# f28e12x_pwm_xbar_regs register map
Vendor: Texas Instruments
Peripheral module from a debugger description file (folder C2000).
Address unit: 16 bits
Registers are 32-bit, read-write, no defined reset value unless marked. A register's access mark holds for its fields unless they carry their own. Offsets are as the file gives them; lines under a group give offsets from that group; [hi:lo] are bit positions; {n}, {i} and the like mark numbered series; 'fields as' and 'values as' point back to an identical list; <NAME> marks a mode.

## PWM_XBAR_REGS — PWM XBAR Registers
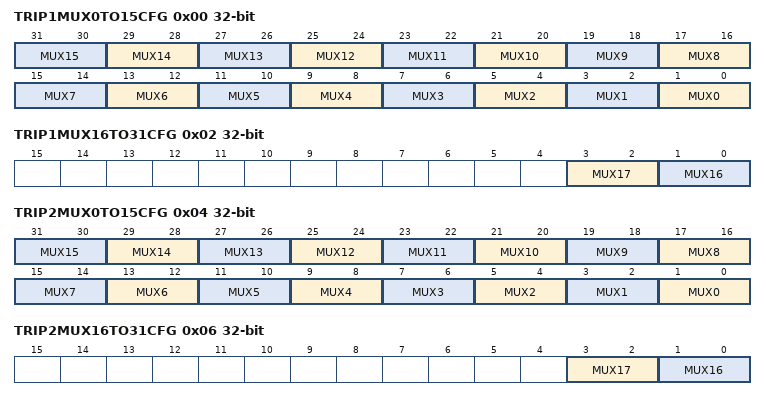
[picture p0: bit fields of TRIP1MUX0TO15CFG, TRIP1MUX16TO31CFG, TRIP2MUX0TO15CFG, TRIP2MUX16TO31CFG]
0x00 TRIP1MUX0TO15CFG — PWM XBAR Mux Configuration for Output1
  [2n+1:2n] MUX{n} (n=0..15) — MUX{n} Configuration for OUT1 of EPWM-XBAR
0x02 TRIP1MUX16TO31CFG — PWM XBAR Mux Configuration for Output1
  [3:2] MUX17 — MUX17 Configuration for OUT1 of EPWM-XBAR
  [1:0] MUX16 — MUX16 Configuration for OUT1 of EPWM-XBAR
0x04 TRIP2MUX0TO15CFG — PWM XBAR Mux Configuration for Output2
  [2n+1:2n] MUX{n} (n=0..15) — MUX{n} Configuration for OUT2 of EPWM-XBAR
0x06 TRIP2MUX16TO31CFG — PWM XBAR Mux Configuration for Output2
  [3:2] MUX17 — MUX17 Configuration for OUT2 of EPWM-XBAR
  [1:0] MUX16 — MUX16 Configuration for OUT2 of EPWM-XBAR
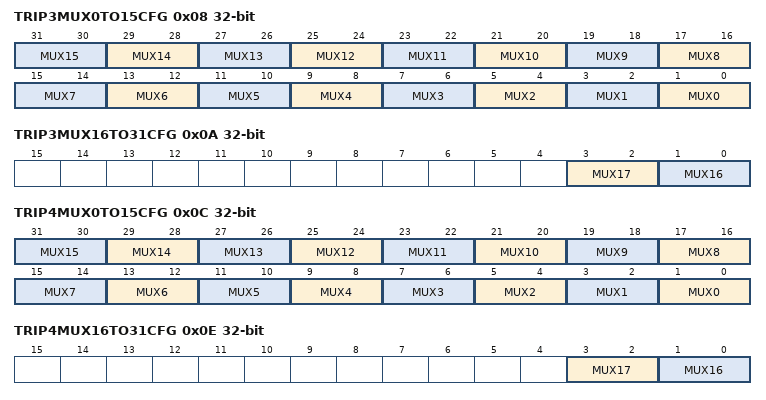
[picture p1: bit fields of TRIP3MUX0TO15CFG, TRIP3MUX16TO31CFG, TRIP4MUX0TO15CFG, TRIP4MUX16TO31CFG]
0x08 TRIP3MUX0TO15CFG — PWM XBAR Mux Configuration for Output3
  [2n+1:2n] MUX{n} (n=0..15) — MUX{n} Configuration for OUT3 of EPWM-XBAR
0x0A TRIP3MUX16TO31CFG — PWM XBAR Mux Configuration for Output3
  [3:2] MUX17 — MUX17 Configuration for OUT3 of EPWM-XBAR
  [1:0] MUX16 — MUX16 Configuration for OUT3 of EPWM-XBAR
0x0C TRIP4MUX0TO15CFG — PWM XBAR Mux Configuration for Output4
  [2n+1:2n] MUX{n} (n=0..15) — MUX{n} Configuration for OUT4 of EPWM-XBAR
0x0E TRIP4MUX16TO31CFG — PWM XBAR Mux Configuration for Output4
  [3:2] MUX17 — MUX17 Configuration for OUT4 of EPWM-XBAR
  [1:0] MUX16 — MUX16 Configuration for OUT4 of EPWM-XBAR
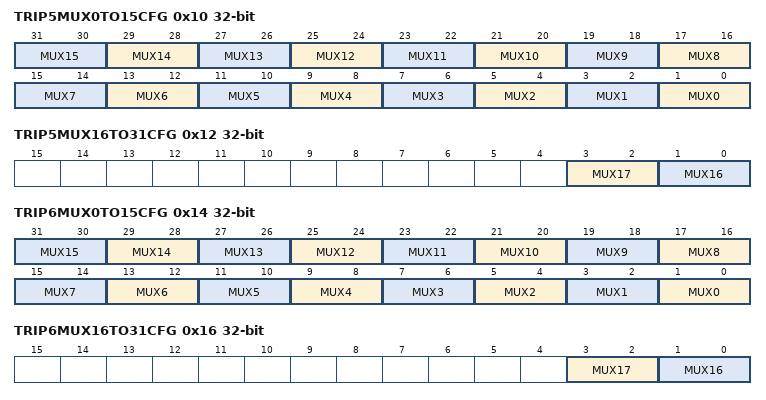
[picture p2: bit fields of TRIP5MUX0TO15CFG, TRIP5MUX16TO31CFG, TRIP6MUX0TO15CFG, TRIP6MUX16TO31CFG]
0x10 TRIP5MUX0TO15CFG — PWM XBAR Mux Configuration for Output5
  [2n+1:2n] MUX{n} (n=0..15) — MUX{n} Configuration for OUT5 of EPWM-XBAR
0x12 TRIP5MUX16TO31CFG — PWM XBAR Mux Configuration for Output5
  [3:2] MUX17 — MUX17 Configuration for OUT5 of EPWM-XBAR
  [1:0] MUX16 — MUX16 Configuration for OUT5 of EPWM-XBAR
0x14 TRIP6MUX0TO15CFG — PWM XBAR Mux Configuration for Output6
  [2n+1:2n] MUX{n} (n=0..15) — MUX{n} Configuration for OUT6 of EPWM-XBAR
0x16 TRIP6MUX16TO31CFG — PWM XBAR Mux Configuration for Output6
  [3:2] MUX17 — MUX17 Configuration for OUT6 of EPWM-XBAR
  [1:0] MUX16 — MUX16 Configuration for OUT6 of EPWM-XBAR
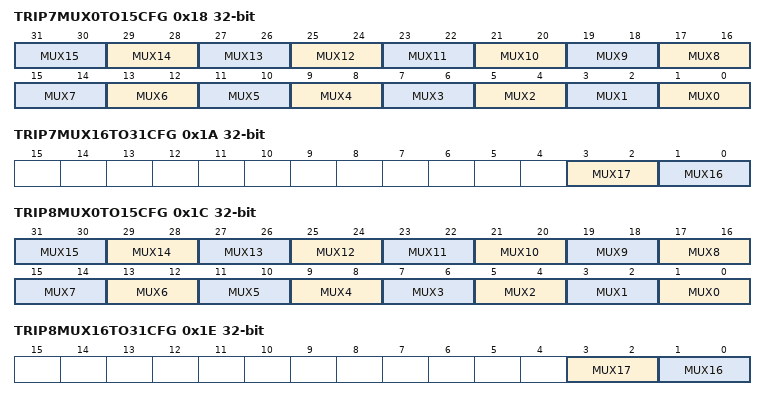
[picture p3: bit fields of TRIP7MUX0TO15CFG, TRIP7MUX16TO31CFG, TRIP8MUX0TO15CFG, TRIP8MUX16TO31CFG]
0x18 TRIP7MUX0TO15CFG — PWM XBAR Mux Configuration for Output7
  [2n+1:2n] MUX{n} (n=0..15) — MUX{n} Configuration for OUT7 of EPWM-XBAR
0x1A TRIP7MUX16TO31CFG — PWM XBAR Mux Configuration for Output7
  [3:2] MUX17 — MUX17 Configuration for OUT7 of EPWM-XBAR
  [1:0] MUX16 — MUX16 Configuration for OUT7 of EPWM-XBAR
0x1C TRIP8MUX0TO15CFG — PWM XBAR Mux Configuration for Output8
  [2n+1:2n] MUX{n} (n=0..15) — MUX{n} Configuration for OUT8 of EPWM-XBAR
0x1E TRIP8MUX16TO31CFG — PWM XBAR Mux Configuration for Output8
  [3:2] MUX17 — MUX17 Configuration for OUT8 of EPWM-XBAR
  [1:0] MUX16 — MUX16 Configuration for OUT8 of EPWM-XBAR
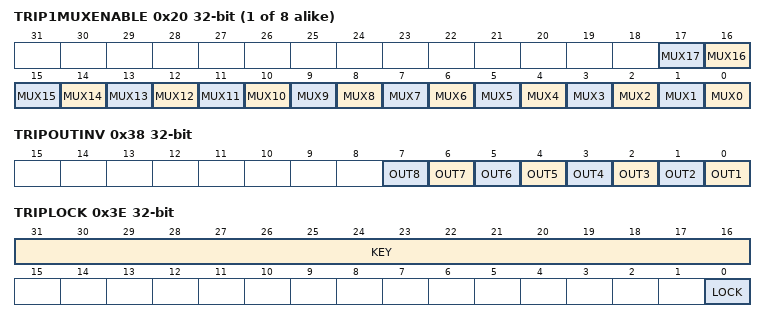
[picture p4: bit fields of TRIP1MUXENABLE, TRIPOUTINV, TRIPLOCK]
{0x1E+2i} TRIP{i}MUXENABLE (i=1..8) — PWM XBAR Mux Enable for Output{i}
  [n] MUX{n} (n=0..17) — MUX{n} to drive OUT{i} of EPWM-XBAR
0x38 TRIPOUTINV — PWM XBAR Output Inversion Register
  [n-1] OUT{n} (n=1..8) — Selects polarity for OUT{n} of EPWM-XBAR
0x3E TRIPLOCK — PWM XBAR Configuration Lock register
  [31:16] KEY — Write protection KEY
  [0] LOCK — Locks the configuration for EPWM-XBAR
